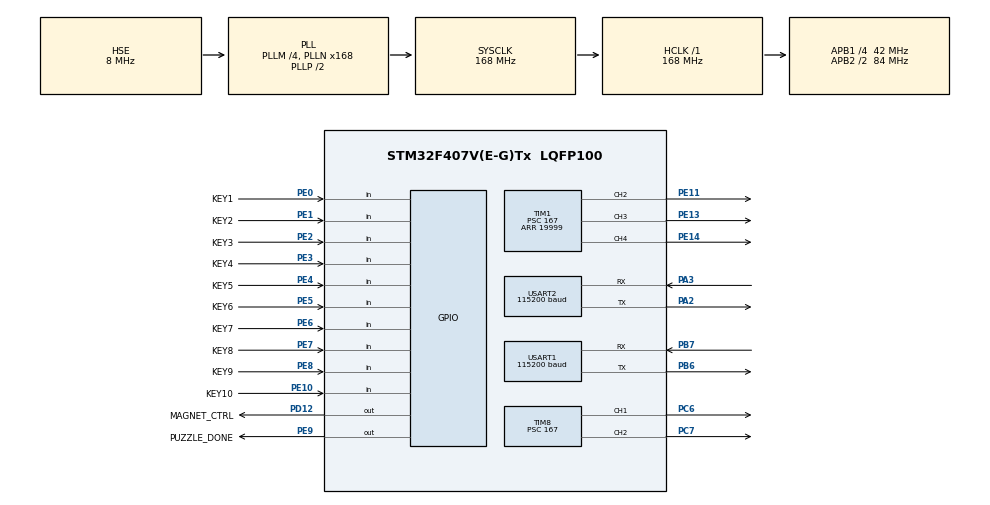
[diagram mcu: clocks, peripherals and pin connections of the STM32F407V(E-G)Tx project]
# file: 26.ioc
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Dma.Request0=USART1_RX
Dma.Request1=USART2_RX
Dma.USART1_RX.0.Direction=DMA_PERIPH_TO_MEMORY
Dma.USART1_RX.0.FIFOMode=DMA_FIFOMODE_DISABLE
Dma.USART1_RX.0.Instance=DMA2_Stream2
Dma.USART1_RX.0.Channel=DMA_CHANNEL_4
Dma.USART1_RX.0.MemDataAlignment=DMA_MDATAALIGN_BYTE
Dma.USART1_RX.0.MemInc=DMA_MINC_ENABLE
Dma.USART1_RX.0.Mode=DMA_NORMAL
Dma.USART1_RX.0.PeriphDataAlignment=DMA_PDATAALIGN_BYTE
Dma.USART1_RX.0.PeriphInc=DMA_PINC_DISABLE
Dma.USART1_RX.0.Priority=DMA_PRIORITY_HIGH
Dma.USART2_RX.1.Direction=DMA_PERIPH_TO_MEMORY
Dma.USART2_RX.1.FIFOMode=DMA_FIFOMODE_DISABLE
Dma.USART2_RX.1.Instance=DMA1_Stream5
Dma.USART2_RX.1.Channel=DMA_CHANNEL_4
Dma.USART2_RX.1.MemDataAlignment=DMA_MDATAALIGN_BYTE
Dma.USART2_RX.1.MemInc=DMA_MINC_ENABLE
Dma.USART2_RX.1.Mode=DMA_NORMAL
Dma.USART2_RX.1.PeriphDataAlignment=DMA_PDATAALIGN_BYTE
Dma.USART2_RX.1.PeriphInc=DMA_PINC_DISABLE
Dma.USART2_RX.1.Priority=DMA_PRIORITY_HIGH
FREERTOS.Tasks01=defaultTask,24,128,StartDefaultTask,Default,NULL,Dynamic,NULL,NULL
Mcu.Family=STM32F4
Mcu.Name=STM32F407V(E-G)Tx
Mcu.Package=LQFP100
NVIC.DMA1_Stream5_IRQn=true\:5\:0\:false\:false\:true\:true\:false\:true\:true
NVIC.DMA2_Stream2_IRQn=true\:5\:0\:false\:false\:true\:true\:false\:true\:true
NVIC.PriorityGroup=NVIC_PRIORITYGROUP_4
NVIC.TIM4_IRQn=true\:15\:0\:false\:false\:true\:false\:false\:true\:true
NVIC.TimeBase=TIM4_IRQn
NVIC.TimeBaseIP=TIM4
NVIC.USART1_IRQn=true\:5\:0\:false\:false\:true\:true\:true\:true\:true
NVIC.USART2_IRQn=true\:5\:0\:false\:false\:true\:true\:true\:true\:true
PA13.Mode=Serial_Wire
PA13.Signal=SYS_JTMS-SWDIO
PA14.Mode=Serial_Wire
PA14.Signal=SYS_JTCK-SWCLK
PA2.Mode=Asynchronous
PA2.Signal=USART2_TX
PA3.Mode=Asynchronous
PA3.Signal=USART2_RX
PB6.Mode=Asynchronous
PB6.Signal=USART1_TX
PB7.Mode=Asynchronous
PB7.Signal=USART1_RX
PC6.Signal=S_TIM8_CH1
PC7.Signal=S_TIM8_CH2
PD12.GPIO_Label=MAGNET_CTRL
PD12.Signal=GPIO_Output
PE11.Signal=S_TIM1_CH2
PE13.Signal=S_TIM1_CH3
PE14.Signal=S_TIM1_CH4
PE0.GPIO_Label=KEY1
PE0.GPIO_PuPd=GPIO_PULLUP
PE0.Signal=GPIO_Input
PE1.GPIO_Label=KEY2
PE1.GPIO_PuPd=GPIO_PULLUP
PE1.Signal=GPIO_Input
PE10.GPIO_Label=KEY10
PE10.GPIO_PuPd=GPIO_PULLUP
PE10.Signal=GPIO_Input
PE2.GPIO_Label=KEY3
PE2.GPIO_PuPd=GPIO_PULLUP
PE2.Signal=GPIO_Input
PE3.GPIO_Label=KEY4
PE3.GPIO_PuPd=GPIO_PULLUP
PE3.Signal=GPIO_Input
PE4.GPIO_Label=KEY5
PE4.GPIO_PuPd=GPIO_PULLUP
PE4.Signal=GPIO_Input
PE5.GPIO_Label=KEY6
PE5.GPIO_PuPd=GPIO_PULLUP
PE5.Signal=GPIO_Input
PE6.GPIO_Label=KEY7
PE6.GPIO_PuPd=GPIO_PULLUP
PE6.Signal=GPIO_Input
PE7.GPIO_Label=KEY8
PE7.GPIO_PuPd=GPIO_PULLUP
PE7.Signal=GPIO_Input
PE8.GPIO_Label=KEY9
PE8.GPIO_PuPd=GPIO_PULLUP
PE8.Signal=GPIO_Input
PE9.GPIO_Label=PUZZLE_DONE
PE9.Signal=GPIO_Output
PH0-OSC_IN.Mode=HSE-External-Oscillator
PH0-OSC_IN.Signal=RCC_OSC_IN
PH1-OSC_OUT.Mode=HSE-External-Oscillator
PH1-OSC_OUT.Signal=RCC_OSC_OUT
ProjectManager.HeapSize=0x200
ProjectManager.StackSize=0x400
ProjectManager.TargetToolchain=MDK-ARM V5.32
RCC.48MHZClocksFreq_Value=48000000
RCC.AHBFreq_Value=168000000
RCC.APB1CLKDivider=RCC_HCLK_DIV4
RCC.APB1Freq_Value=42000000
RCC.APB1TimFreq_Value=84000000
RCC.APB2CLKDivider=RCC_HCLK_DIV2
RCC.APB2Freq_Value=84000000
RCC.APB2TimFreq_Value=168000000
RCC.CortexFreq_Value=168000000
RCC.HCLKFreq_Value=168000000
RCC.HSE_VALUE=8000000
RCC.HSI_VALUE=16000000
RCC.LSE_VALUE=32768
RCC.PLLM=4
RCC.PLLN=168
RCC.PLLQ=7
RCC.PLLSourceVirtual=RCC_PLLSOURCE_HSE
RCC.SYSCLKFreq_VALUE=168000000
RCC.SYSCLKSource=RCC_SYSCLKSOURCE_PLLCLK
RCC.VCOOutputFreq_Value=336000000
SH.S_TIM1_CH2.0=TIM1_CH2,PWM Generation2 CH2
SH.S_TIM1_CH3.0=TIM1_CH3,PWM Generation3 CH3
SH.S_TIM1_CH4.0=TIM1_CH4,PWM Generation4 CH4
SH.S_TIM8_CH1.0=TIM8_CH1,PWM Generation1 CH1
SH.S_TIM8_CH2.0=TIM8_CH2,PWM Generation2 CH2
TIM1.Channel-PWM\ Generation2\ CH2=TIM_CHANNEL_2
TIM1.Channel-PWM\ Generation3\ CH3=TIM_CHANNEL_3
TIM1.Channel-PWM\ Generation4\ CH4=TIM_CHANNEL_4
TIM1.Period=19999
TIM1.Prescaler=167
TIM8.Channel-PWM\ Generation1\ CH1=TIM_CHANNEL_1
TIM8.Channel-PWM\ Generation2\ CH2=TIM_CHANNEL_2
TIM8.Period=19999
TIM8.Prescaler=167
USART1.BaudRate=115200
USART1.VirtualMode=VM_ASYNC
USART2.BaudRate=115200
USART2.VirtualMode=VM_ASYNC
VP_FREERTOS_VS_CMSIS_V2.Mode=CMSIS_V2
VP_SYS_VS_tim4.Mode=TIM4
board=custom

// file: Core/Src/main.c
/* USER CODE BEGIN Header */
/**
  ******************************************************************************
  * @file           : main.c
  * @brief          : Main program body
  ******************************************************************************
  * @attention
  *
  * Copyright (c) 2026 STMicroelectronics.
  * All rights reserved.
  *
  * This software is licensed under terms that can be found in the LICENSE file
  * in the root directory of this software component.
  * If no LICENSE file comes with this software, it is provided AS-IS.
  *
  ******************************************************************************
  */
/* USER CODE END Header */
#include "main.h"
#include "cmsis_os.h"
#include "tim.h"
#include "usart.h"
#include "gpio.h"

/* USER CODE BEGIN Includes */
#include "arm_app.h"
/* USER CODE END Includes */

void SystemClock_Config(void);
void MX_FREERTOS_Init(void);

int main(void)
{

  /* MCU Configuration--------------------------------------------------------*/

  /* Reset of all peripherals, Initializes the Flash interface and the Systick. */
  HAL_Init();

  /* Configure the system clock */
  SystemClock_Config();

  /* Initialize all configured peripherals */
  MX_GPIO_Init();
  MX_TIM1_Init();
  MX_TIM8_Init();
  MX_USART1_UART_Init();
  MX_USART2_UART_Init();
  /* USER CODE BEGIN 2 */
  if (!ArmApp_HardwareInit())
  {
    Error_Handler();
  }
  /* USER CODE END 2 */

  /* Init scheduler */
  osKernelInitialize();

  /* Call init function for freertos objects (in cmsis_os2.c) */
  MX_FREERTOS_Init();

  /* Start scheduler */
  osKernelStart();

  /* We should never get here as control is now taken by the scheduler */

  /* Infinite loop */
  while (1)
  {

  }
}

void SystemClock_Config(void)
{
  RCC_OscInitTypeDef RCC_OscInitStruct = {0};
  RCC_ClkInitTypeDef RCC_ClkInitStruct = {0};

  /** Configure the main internal regulator output voltage
  */
  __HAL_RCC_PWR_CLK_ENABLE();
  __HAL_PWR_VOLTAGESCALING_CONFIG(PWR_REGULATOR_VOLTAGE_SCALE1);

  /** Initializes the RCC Oscillators according to the specified parameters
  * in the RCC_OscInitTypeDef structure.
  */
  RCC_OscInitStruct.OscillatorType = RCC_OSCILLATORTYPE_HSE;
  RCC_OscInitStruct.HSEState = RCC_HSE_ON;
  RCC_OscInitStruct.PLL.PLLState = RCC_PLL_ON;
  RCC_OscInitStruct.PLL.PLLSource = RCC_PLLSOURCE_HSE;
  RCC_OscInitStruct.PLL.PLLM = 4;
  RCC_OscInitStruct.PLL.PLLN = 168;
  RCC_OscInitStruct.PLL.PLLP = RCC_PLLP_DIV2;
  RCC_OscInitStruct.PLL.PLLQ = 7;
  if (HAL_RCC_OscConfig(&RCC_OscInitStruct) != HAL_OK)
  {
    Error_Handler();
  }

  /** Initializes the CPU, AHB and APB buses clocks
  */
  RCC_ClkInitStruct.ClockType = RCC_CLOCKTYPE_HCLK|RCC_CLOCKTYPE_SYSCLK
                              |RCC_CLOCKTYPE_PCLK1|RCC_CLOCKTYPE_PCLK2;
  RCC_ClkInitStruct.SYSCLKSource = RCC_SYSCLKSOURCE_PLLCLK;
  RCC_ClkInitStruct.AHBCLKDivider = RCC_SYSCLK_DIV1;
  RCC_ClkInitStruct.APB1CLKDivider = RCC_HCLK_DIV4;
  RCC_ClkInitStruct.APB2CLKDivider = RCC_HCLK_DIV2;

  if (HAL_RCC_ClockConfig(&RCC_ClkInitStruct, FLASH_LATENCY_5) != HAL_OK)
  {
    Error_Handler();
  }
}

void HAL_TIM_PeriodElapsedCallback(TIM_HandleTypeDef *htim)
{
  if (htim->Instance == TIM4)
  {
    HAL_IncTick();
  }
}

void Error_Handler(void)
{
  __disable_irq();
  while (1)
  {
  }
}

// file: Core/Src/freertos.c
/* USER CODE BEGIN Header */
/**
  ******************************************************************************
  * File Name          : freertos.c
  * Description        : Code for freertos applications
  ******************************************************************************
  * @attention
  *
  * Copyright (c) 2026 STMicroelectronics.
  * All rights reserved.
  *
  * This software is licensed under terms that can be found in the LICENSE file
  * in the root directory of this software component.
  * If no LICENSE file comes with this software, it is provided AS-IS.
  *
  ******************************************************************************
  */
/* USER CODE END Header */

#include "FreeRTOS.h"
#include "task.h"
#include "main.h"
#include "cmsis_os.h"

/* USER CODE BEGIN Includes */
#include "arm_app.h"
/* USER CODE END Includes */

/* Definitions for defaultTask */
osThreadId_t defaultTaskHandle;
const osThreadAttr_t defaultTask_attributes = {
  .name = "defaultTask",
  .stack_size = 128 * 4,
  .priority = (osPriority_t) osPriorityNormal,
};

void StartDefaultTask(void *argument);

void MX_FREERTOS_Init(void); /* (MISRA C 2004 rule 8.1) */

void MX_FREERTOS_Init(void) {

  /* Create the thread(s) */
  /* creation of defaultTask */
  defaultTaskHandle = osThreadNew(StartDefaultTask, NULL, &defaultTask_attributes);

  /* USER CODE BEGIN RTOS_THREADS */
  if (!ArmApp_RtosInit())
  {
    Error_Handler();
  }
  /* USER CODE END RTOS_THREADS */

}

void StartDefaultTask(void *argument)
{
  /* USER CODE BEGIN StartDefaultTask */
  /* Infinite loop */
  for(;;)
  {
    osDelay(1000);
  }
  /* USER CODE END StartDefaultTask */
}
